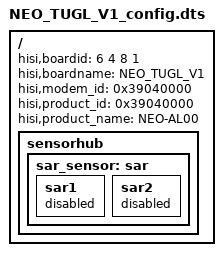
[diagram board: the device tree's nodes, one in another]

/**
 * Copyright (C) 2014 Hisilicon Ltd.
 *
 *  This program is free software; you can redistribute it and/or modify
 *  it under the terms of the GNU General Public License version 2 as
 *  publishhed by the Free Software Foundation.
 */

/dts-v1/;
/include/ "fastboot.dtsi"
/include/ "NEO_TUGL_V0_config.dtsi"
/include/ "NEO_TUGL_V1_pin.dtsi"
/include/ "NEO_TUGL_V1_modem_pin.dtsi"

/ {
	hisi,boardid = <6 4 8 1>;
	hisi,boardname = "NEO_TUGL_V1";
	hisi,modem_id = <0x39040000>;
	hisi,product_id = <0x39040000>;
	hisi,product_name = "NEO-AL00";
	sensorhub{
		sar_sensor:sar{
			sar1{
				status = "disabled";
			};
			sar2{
				status = "disabled";
			};
		};
	};
};
